# STM32G473 register map
File version: 2.2
CPU: CM4 r0p1, little endian, MPU, FPU, 4 interrupt priority bits
Registers are 32-bit, read-write, reset 0x0 unless marked. A register's access mark holds for its fields unless they carry their own. Offsets are from the block's base; [hi:lo] are bit positions; {n}, {i} and the like mark numbered series; 'fields as' and 'values as' point back to an identical list; <NAME> marks a mode.

## RCC — Reset and clock control
Base 0x40021000
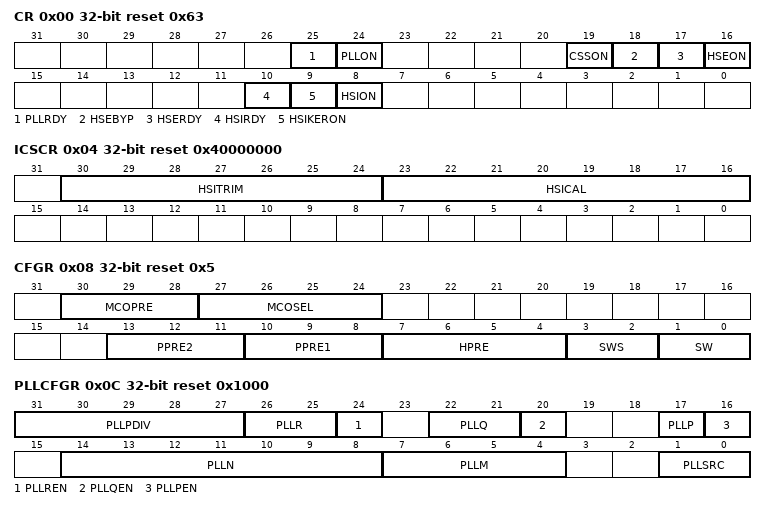
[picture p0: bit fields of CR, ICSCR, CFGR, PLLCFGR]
0x00 CR access per field reset 0x63 — Clock control register
  [25] PLLRDY ro — Main PLL clock ready flag Set by hardware to indicate that the main PLL is locked.
    0=NotReady (Clock not ready); 1=Ready (Clock ready)
  [24] PLLON rw — Main PLL enable Set and cleared by software to enable the main PLL. Cleared by hardware when entering Stop, Standby or Shutdown mode. This bit cannot be reset if the PLL clock is used as the system clock.
    0=Off (Clock Off); 1=On (Clock On)
  [19] CSSON rw — Clock security system enable Set by software to enable the clock security system. When CSSON is set, the clock detector is enabled by hardware when the HSE oscillator is ready, and disabled by hardware if a HSE clock failure is detected. This bit is set only and is cleared by reset.
    0=Off (Clock security system disabled (clock detector OFF)); 1=On (Clock security system enable (clock detector ON if the HSE is ready, OFF if not))
  [18] HSEBYP rw — HSE crystal oscillator bypass Set and cleared by software to bypass the oscillator with an external clock. The external clock must be enabled with the HSEON bit set, to be used by the device. The HSEBYP bit can be written only if the HSE oscillator is disabled.
    0=NotBypassed (HSE crystal oscillator not bypassed); 1=Bypassed (HSE crystal oscillator bypassed with external clock)
  [17] HSERDY ro — HSE clock ready flag Set by hardware to indicate that the HSE oscillator is stable. Note: Once the HSEON bit is cleared, HSERDY goes low after 6 HSE clock cycles.
    0=NotReady (Clock not ready); 1=Ready (Clock ready)
  [16] HSEON rw — HSE clock enable Set and cleared by software. Cleared by hardware to stop the HSE oscillator when entering Stop, Standby or Shutdown mode. This bit cannot be reset if the HSE oscillator is used directly or indirectly as the system clock.
    0=Off (Clock Off); 1=On (Clock On)
  [10] HSIRDY ro — HSI16 clock ready flag Set by hardware to indicate that HSI16 oscillator is stable. This bit is set only when HSI16 is enabled by software by setting HSION. Note: Once the HSION bit is cleared, HSIRDY goes low after 6 HSI16 clock cycles.
    0=NotReady (Clock not ready); 1=Ready (Clock ready)
  [9] HSIKERON rw — HSI16 always enable for peripheral kernels. Set and cleared by software to force HSI16 ON even in Stop modes. The HSI16 can only feed USARTs and I<sup>2</sup>Cs peripherals configured with HSI16 as kernel clock. Keeping the HSI16 ON in Stop mode allows to avoid slowing down the communication speed because of the HSI16 startup time. This bit has no effect on HSION value.
  [8] HSION rw — HSI16 clock enable Set and cleared by software. Cleared by hardware to stop the HSI16 oscillator when entering Stop, Standby or Shutdown mode. Set by hardware to force the HSI16 oscillator ON when STOPWUCK=1 or HSIASFS = 1 when leaving Stop modes, or in case of failure of the HSE crystal oscillator. This bit is set by hardware if the HSI16 is used directly or indirectly as system clock.
    0=Off (Clock Off); 1=On (Clock On)
0x04 ICSCR access per field reset 0x40000000 — Internal clock sources calibration register
  [30:24] HSITRIM rw — HSI16 clock trimming These bits provide an additional user-programmable trimming value that is added to the HSICAL[7:0] bits. It can be programmed to adjust to variations in voltage and temperature that influence the frequency of the HSI16. The default value is 16, which, when added to the HSICAL value, should trim the HSI16 to 16 MHz 1 %.
  [23:16] HSICAL ro — HSI16 clock calibration These bits are initialized at startup with the factory-programmed HSI16 calibration trim value. When HSITRIM is written, HSICAL is updated with the sum of HSITRIM and the factory trim value.
0x08 CFGR access per field reset 0x5 — Clock configuration register
  [30:28] MCOPRE rw — Microcontroller clock output prescaler These bits are set and cleared by software. It is highly recommended to change this prescaler before MCO output is enabled. Others: not allowed
    0=Div1 (MCO divided by 1); 1=Div2 (MCO divided by 2); 2=Div4 (MCO divided by 4); 3=Div8 (MCO divided by 8); 4=Div16 (MCO divided by 16)
  [27:24] MCOSEL rw — Microcontroller clock output Set and cleared by software. Others: Reserved Note: This clock output may have some truncated cycles at startup or during MCO clock source switching.
    0=None (MCO output disabled, no clock on MCO); 1=SYSCLK (SYSCLK system clock selected); 2=MSI (MSI clock selected); 3=HSI (HSI clock selected); 4=HSE (HSE clock selected); 5=PLL (Main PLL clock selected); 6=LSI (LSI clock selected); 7=LSE (LSE clock selected); 8=HSI48 (Internal HSI48 clock selected)
  [13:11] PPRE2 rw — APB2 prescaler Set and cleared by software to control the division factor of the APB2 clock (PCLK2). 0xx: HCLK not divided
    4=Div2 (HCLK divided by 2); 5=Div4 (HCLK divided by 4); 6=Div8 (HCLK divided by 8); 7=Div16 (HCLK divided by 16); other=Div1 (HCLK not divided)
  [10:8] PPRE1 rw — APB1 prescaler Set and cleared by software to control the division factor of the APB1 clock (PCLK1). 0xx: HCLK not divided
    values as PPRE2
  [7:4] HPRE rw — AHB prescaler Set and cleared by software to control the division factor of the AHB clock. Note: Depending on the device voltage range, the software has to set correctly these bits to ensure that the system frequency does not exceed the maximum allowed frequency (for more details please refer to Section 6.1.5: Dynamic voltage scaling management). After a write operation to these bits and before decreasing the voltage range, this register must be read to be sure that the new value has been taken into account. 0xxx: SYSCLK not divided
    8=Div2 (SYSCLK divided by 2); 9=Div4 (SYSCLK divided by 4); 10=Div8 (SYSCLK divided by 8); 11=Div16 (SYSCLK divided by 16); 12=Div64 (SYSCLK divided by 64); 13=Div128 (SYSCLK divided by 128); 14=Div256 (SYSCLK divided by 256); 15=Div512 (SYSCLK divided by 512); other=Div1 (SYSCLK not divided)
  [3:2] SWS ro — System clock switch status Set and cleared by hardware to indicate which clock source is used as system clock.
    0=MSI (MSI oscillator used as system clock); 1=HSI (HSI oscillator used as system clock); 2=HSE (HSE used as system clock); 3=PLL (PLL used as system clock)
  [1:0] SW rw — System clock switch Set and cleared by software to select system clock source (SYSCLK). Configured by hardware to force HSI16 oscillator selection when exiting stop and standby modes or in case of failure of the HSE oscillator.
    0=MSI (MSI selected as system clock); 1=HSI (HSI selected as system clock); 2=HSE (HSE selected as system clock); 3=PLL (PLL selected as system clock)
0x0C PLLCFGR reset 0x1000 — PLL configuration register
  [31:27] PLLPDIV — Main PLLP division factor Set and cleared by software to control the PLL P frequency. PLL P output clock frequency = VCO frequency / PLLPDIV. ....
    0=PLLP (pll_p_ck is controlled by PLLP); {v}=Div{v} (pll_p_ck = vco_ck / {v}) (v=2..31)
  [26:25] PLLR — Main PLL division factor for PLL R clock (system clock) Set and cleared by software to control the frequency of the main PLL output clock PLLCLK. This output can be selected as system clock. These bits can be written only if PLL is disabled. PLL R output clock frequency = VCO frequency / PLLR with PLLR = 2, 4, 6, or 8 Note: The software has to set these bits correctly not to exceed 170 MHz on this domain.
    0=Div2 (pll_r_ck = vco_ck / 2); 1=Div4 (pll_r_ck = vco_ck / 4); 2=Div6 (pll_r_ck = vco_ck / 6); 3=Div8 (pll_r_ck = vco_ck / 8)
  [24] PLLREN — PLL R clock output enable Set and reset by software to enable the PLL R clock output of the PLL (used as system clock). This bit cannot be written when PLL R clock output of the PLL is used as System Clock. In order to save power, when the PLL R clock output of the PLL is not used, the value of PLLREN should be 0.
  [22:21] PLLQ — Main PLL division factor for PLL Q clock. Set and cleared by software to control the frequency of the main PLL output clock PLL Q clock. This output can be selected for USB, RNG, SAI (48 MHz clock). These bits can be written only if PLL is disabled. PLL Q output clock frequency = VCO frequency / PLLQ with PLLQ = 2, 4, 6, or 8 Note: The software has to set these bits correctly not to exceed 170 MHz on this domain.
    0=Div2 (pll_q_ck = vco_ck / 2); 1=Div4 (pll_q_ck = vco_ck / 4); 2=Div6 (pll_q_ck = vco_ck / 6); 3=Div8 (pll_q_ck = vco_ck / 8)
  [20] PLLQEN — Main PLL Q clock output enable Set and reset by software to enable the PLL Q clock output of the PLL. In order to save power, when the PLL Q clock output of the PLL is not used, the value of PLLQEN should be 0.
  [17] PLLP — Main PLL division factor for PLL P clock. Set and cleared by software to control the frequency of the main PLL output clock PLL P clock. These bits can be written only if PLL is disabled. When the PLLPDIV[4:0] is set to 00000PLL P output clock frequency = VCO frequency / PLLP with PLLP =7, or 17 Note: The software has to set these bits correctly not to exceed 170 MHz on this domain.
    0=Div7 (pll_p_ck = vco_ck / 7); 1=Div17 (pll_p_ck = vco_ck / 17)
  [16] PLLPEN — Main PLL PLL P clock output enable Set and reset by software to enable the PLL P clock output of the PLL. In order to save power, when the PLL P clock output of the PLL is not used, the value of PLLPEN should be 0.
  [14:8] PLLN — Main PLL multiplication factor for VCO Set and cleared by software to control the multiplication factor of the VCO. These bits can be written only when the PLL is disabled. VCO output frequency = VCO input frequency x PLLN with 8 =< PLLN =< 127 ... ... Note: The software has to set correctly these bits to assure that the VCO output frequency is within the range defined in the device datasheet.
    {v}=Div{v} (pll_n_ck = vco_ck / {v}) (v=8..127)
  [7:4] PLLM — Division factor for the main PLL input clock Set and cleared by software to divide the PLL input clock before the VCO. These bits can be written only when all PLLs are disabled. VCO input frequency = PLL input clock frequency / PLLM with 1 <= PLLM <= 16 ... Note: The software has to set these bits correctly to ensure that the VCO input frequency is within the range defined in the device datasheet.
    {v}=Div{v+1} (pll_p_ck = vco_ck / {v+1}) (v=0..15)
  [1:0] PLLSRC — Main PLL entry clock source Set and cleared by software to select PLL clock source. These bits can be written only when PLL is disabled. In order to save power, when no PLL is used, the value of PLLSRC should be 00.
    0=None (No clock sent to PLL); 2=HSI16 (HSI16 sent to PLL input); 3=HSE (HSE sent to PLL input)
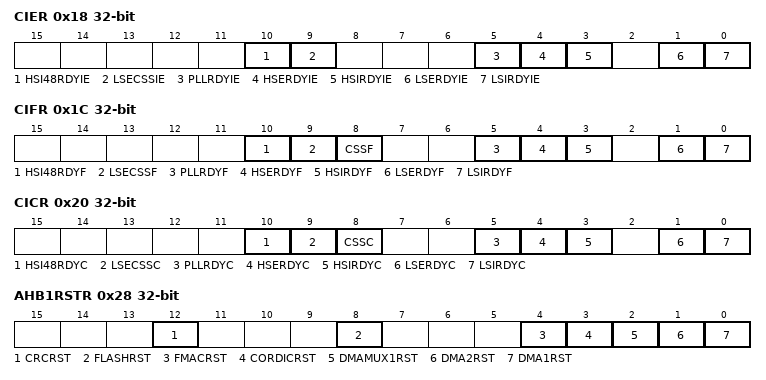
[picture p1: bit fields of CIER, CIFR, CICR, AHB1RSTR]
0x18 CIER — Clock interrupt enable register
  [10] HSI48RDYIE — HSI48 ready interrupt enable Set and cleared by software to enable/disable interrupt caused by the internal HSI48 oscillator.
  [9] LSECSSIE — LSE clock security system interrupt enable Set and cleared by software to enable/disable interrupt caused by the clock security system on LSE.
  [5] PLLRDYIE — PLL ready interrupt enable Set and cleared by software to enable/disable interrupt caused by PLL lock.
  [4] HSERDYIE — HSE ready interrupt enable Set and cleared by software to enable/disable interrupt caused by the HSE oscillator stabilization.
  [3] HSIRDYIE — HSI16 ready interrupt enable Set and cleared by software to enable/disable interrupt caused by the HSI16 oscillator stabilization.
  [1] LSERDYIE — LSE ready interrupt enable Set and cleared by software to enable/disable interrupt caused by the LSE oscillator stabilization.
  [0] LSIRDYIE — LSI ready interrupt enable Set and cleared by software to enable/disable interrupt caused by the LSI oscillator stabilization.
0x1C CIFR ro — Clock interrupt flag register
  [10] HSI48RDYF — HSI48 ready interrupt flag Set by hardware when the HSI48 clock becomes stable and HSI48RDYIE is set in a response to setting the HSI48ON (refer to Clock recovery RC register (RCC_CRRCR)). Cleared by software setting the HSI48RDYC bit.
  [9] LSECSSF — LSE Clock security system interrupt flag Set by hardware when a failure is detected in the LSE oscillator. Cleared by software setting the LSECSSC bit.
  [8] CSSF — Clock security system interrupt flag Set by hardware when a failure is detected in the HSE oscillator. Cleared by software setting the CSSC bit.
  [5] PLLRDYF — PLL ready interrupt flag Set by hardware when the PLL locks and PLLRDYDIE is set. Cleared by software setting the PLLRDYC bit.
  [4] HSERDYF — HSE ready interrupt flag Set by hardware when the HSE clock becomes stable and HSERDYDIE is set. Cleared by software setting the HSERDYC bit.
  [3] HSIRDYF — HSI16 ready interrupt flag Set by hardware when the HSI16 clock becomes stable and HSIRDYDIE is set in a response to setting the HSION (refer to Clock control register (RCC_CR)). When HSION is not set but the HSI16 oscillator is enabled by the peripheral through a clock request, this bit is not set and no interrupt is generated. Cleared by software setting the HSIRDYC bit.
  [1] LSERDYF — LSE ready interrupt flag Set by hardware when the LSE clock becomes stable and LSERDYDIE is set. Cleared by software setting the LSERDYC bit.
  [0] LSIRDYF — LSI ready interrupt flag Set by hardware when the LSI clock becomes stable and LSIRDYDIE is set. Cleared by software setting the LSIRDYC bit.
0x20 CICR wo — Clock interrupt clear register
  [10] HSI48RDYC — HSI48 oscillator ready interrupt clear This bit is set by software to clear the HSI48RDYF flag.
  [9] LSECSSC — LSE Clock security system interrupt clear This bit is set by software to clear the LSECSSF flag.
  [8] CSSC — Clock security system interrupt clear This bit is set by software to clear the CSSF flag.
  [5] PLLRDYC — PLL ready interrupt clear This bit is set by software to clear the PLLRDYF flag.
  [4] HSERDYC — HSE ready interrupt clear This bit is set by software to clear the HSERDYF flag.
  [3] HSIRDYC — HSI16 ready interrupt clear This bit is set software to clear the HSIRDYF flag.
  [1] LSERDYC — LSE ready interrupt clear This bit is set by software to clear the LSERDYF flag.
  [0] LSIRDYC — LSI ready interrupt clear This bit is set by software to clear the LSIRDYF flag.
0x28 AHB1RSTR — AHB1 peripheral reset register
  [all] fields
    1=Reset the selected module
  [12] CRCRST — CRC reset Set and cleared by software.
  [8] FLASHRST — Flash memory interface reset Set and cleared by software. This bit can be activated only when the Flash memory is in power down mode.
  [4] FMACRST — Set and cleared by software
  [3] CORDICRST — Set and cleared by software
  [2] DMAMUX1RST — Set and cleared by software.
  [1] DMA2RST — DMA2 reset Set and cleared by software.
  [0] DMA1RST — DMA1 reset Set and cleared by software.
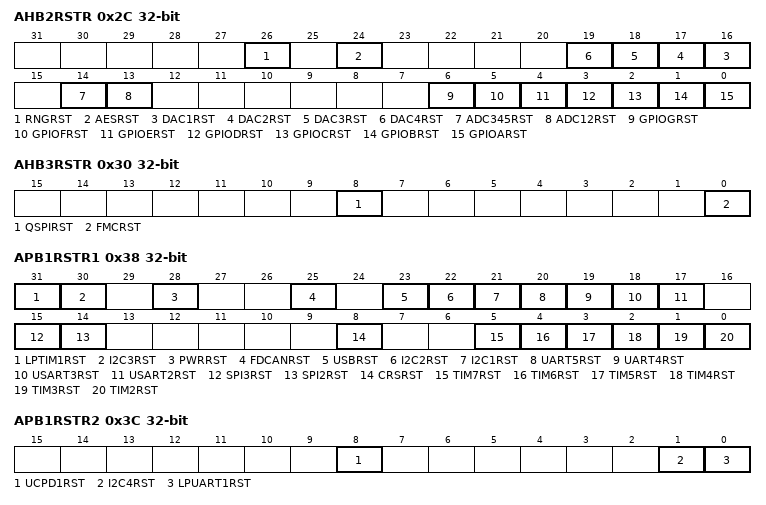
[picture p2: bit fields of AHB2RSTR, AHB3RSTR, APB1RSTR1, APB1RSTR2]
0x2C AHB2RSTR — AHB2 peripheral reset register
  [all] fields
    1=Reset the selected module
  [26] RNGRST — RNG reset Set and cleared by software.
  [24] AESRST — AESRST reset Set and cleared by software.
  [n+15] DAC{n}RST (n=1..4) — DAC{n} reset Set and cleared by software.
  [14] ADC345RST — ADC345 reset Set and cleared by software.
  [13] ADC12RST — ADC12 reset Set and cleared by software.
  [6] GPIOGRST — IO port G reset Set and cleared by software.
  [5] GPIOFRST — IO port F reset Set and cleared by software.
  [4] GPIOERST — IO port E reset Set and cleared by software.
  [3] GPIODRST — IO port D reset Set and cleared by software.
  [2] GPIOCRST — IO port C reset Set and cleared by software.
  [1] GPIOBRST — IO port B reset Set and cleared by software.
  [0] GPIOARST — IO port A reset Set and cleared by software.
0x30 AHB3RSTR — AHB3 peripheral reset register
  [8] QSPIRST — QUADSPI reset Set and cleared by software.
    1=Reset the selected module
  [0] FMCRST — Flexible static memory controller reset Set and cleared by software.
    1=Reset the selected module
0x38 APB1RSTR1 — APB1 peripheral reset register 1
  [all] fields
    1=Reset the selected module
  [31] LPTIM1RST — Low Power Timer 1 reset Set and cleared by software.
  [30] I2C3RST — I2C3 reset Set and cleared by software.
  [28] PWRRST — Power interface reset Set and cleared by software.
  [25] FDCANRST — FDCAN reset Set and reset by software.
  [23] USBRST — USB device reset Set and reset by software.
  [22] I2C2RST — I2C2 reset Set and cleared by software.
  [21] I2C1RST — I2C1 reset Set and cleared by software.
  [20] UART5RST — UART5 reset Set and cleared by software.
  [19] UART4RST — UART4 reset Set and cleared by software.
  [18] USART3RST — USART3 reset Set and cleared by software.
  [17] USART2RST — USART2 reset Set and cleared by software.
  [15] SPI3RST — SPI3 reset Set and cleared by software.
  [14] SPI2RST — SPI2 reset Set and cleared by software.
  [8] CRSRST — CRS reset Set and cleared by software.
  [5] TIM7RST — TIM7 timer reset Set and cleared by software.
  [4] TIM6RST — TIM6 timer reset Set and cleared by software.
  [3] TIM5RST — TIM5 timer reset Set and cleared by software.
  [2] TIM4RST — TIM3 timer reset Set and cleared by software.
  [1] TIM3RST — TIM3 timer reset Set and cleared by software.
  [0] TIM2RST — TIM2 timer reset Set and cleared by software.
0x3C APB1RSTR2 — APB1 peripheral reset register 2
  [all] fields
    1=Reset the selected module
  [8] UCPD1RST — UCPD1 reset Set and cleared by software.
  [1] I2C4RST — I2C4 reset Set and cleared by software
  [0] LPUART1RST — Low-power UART 1 reset Set and cleared by software.
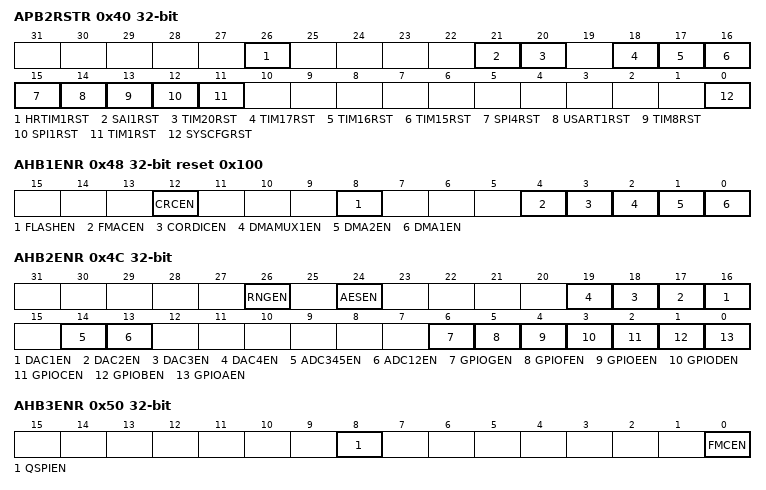
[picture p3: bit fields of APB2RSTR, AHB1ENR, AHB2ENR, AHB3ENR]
0x40 APB2RSTR — APB2 peripheral reset register
  [all] fields
    1=Reset the selected module
  [26] HRTIM1RST — HRTIM1 reset Set and cleared by software.
  [21] SAI1RST — Serial audio interface 1 (SAI1) reset Set and cleared by software.
  [20] TIM20RST — TIM20 reset Set and cleared by software.
  [18] TIM17RST — TIM17 timer reset Set and cleared by software.
  [17] TIM16RST — TIM16 timer reset Set and cleared by software.
  [16] TIM15RST — TIM15 timer reset Set and cleared by software.
  [15] SPI4RST — SPI4 reset Set and cleared by software.
  [14] USART1RST — USART1 reset Set and cleared by software.
  [13] TIM8RST — TIM8 timer reset Set and cleared by software.
  [12] SPI1RST — SPI1 reset Set and cleared by software.
  [11] TIM1RST — TIM1 timer reset Set and cleared by software.
  [0] SYSCFGRST — SYSCFG + COMP + OPAMP + VREFBUF reset
0x48 AHB1ENR reset 0x100 — AHB1 peripheral clock enable register
  [all] fields
    0=Disabled (The selected clock is disabled); 1=Enabled (The selected clock is enabled)
  [12] CRCEN — CRC clock enable Set and cleared by software.
  [8] FLASHEN — Flash memory interface clock enable Set and cleared by software. This bit can be disabled only when the Flash is in power down mode.
  [4] FMACEN — FMAC enable Set and reset by software.
  [3] CORDICEN — CORDIC clock enable Set and reset by software.
  [2] DMAMUX1EN — DMAMUX1 clock enable Set and reset by software.
  [1] DMA2EN — DMA2 clock enable Set and cleared by software.
  [0] DMA1EN — DMA1 clock enable Set and cleared by software.
0x4C AHB2ENR — AHB2 peripheral clock enable register
  [all] fields
    values as the fields of AHB1ENR
  [26] RNGEN — RNG enable Set and cleared by software.
  [24] AESEN — AES clock enable Set and cleared by software.
  [n+15] DAC{n}EN (n=1..4) — DAC{n} clock enable Set and cleared by software.
  [14] ADC345EN — ADC345 clock enable Set and cleared by software
  [13] ADC12EN — ADC12 clock enable Set and cleared by software.
  [6] GPIOGEN — IO port G clock enable Set and cleared by software.
  [5] GPIOFEN — IO port F clock enable Set and cleared by software.
  [4] GPIOEEN — IO port E clock enable Set and cleared by software.
  [3] GPIODEN — IO port D clock enable Set and cleared by software.
  [2] GPIOCEN — IO port C clock enable Set and cleared by software.
  [1] GPIOBEN — IO port B clock enable Set and cleared by software.
  [0] GPIOAEN — IO port A clock enable Set and cleared by software.
0x50 AHB3ENR — AHB3 peripheral clock enable register
  [8] QSPIEN — QUADSPI memory interface clock enable Set and cleared by software.
    values as the fields of AHB1ENR
  [0] FMCEN — Flexible static memory controller clock enable Set and cleared by software.
    values as the fields of AHB1ENR
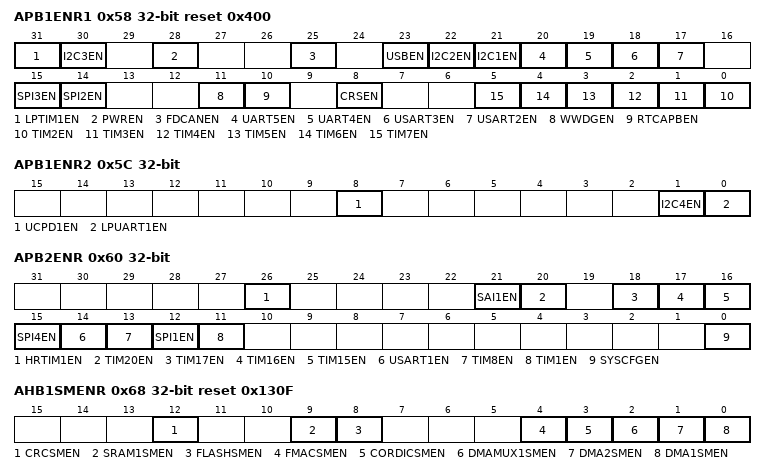
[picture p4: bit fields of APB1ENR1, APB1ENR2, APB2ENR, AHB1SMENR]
0x58 APB1ENR1 reset 0x400 — APB1 peripheral clock enable register 1
  [all] fields
    values as the fields of AHB1ENR
  [31] LPTIM1EN — Low power timer 1 clock enable Set and cleared by software.
  [30] I2C3EN — I2C3 clock enable Set and cleared by software.
  [28] PWREN — Power interface clock enable Set and cleared by software.
  [25] FDCANEN — FDCAN clock enable Set and cleared by software.
  [23] USBEN — USB device clock enable Set and cleared by software.
  [22] I2C2EN — I2C2 clock enable Set and cleared by software.
  [21] I2C1EN — I2C1 clock enable Set and cleared by software.
  [20] UART5EN — UART5 clock enable Set and cleared by software.
  [19] UART4EN — UART4 clock enable Set and cleared by software.
  [18] USART3EN — USART3 clock enable Set and cleared by software.
  [17] USART2EN — USART2 clock enable Set and cleared by software.
  [15] SPI3EN — SPI3 clock enable Set and cleared by software.
  [14] SPI2EN — SPI2 clock enable Set and cleared by software.
  [11] WWDGEN — Window watchdog clock enable Set by software to enable the window watchdog clock. Reset by hardware system reset. This bit can also be set by hardware if the WWDG_SW option bit is reset.
  [10] RTCAPBEN — RTC APB clock enable Set and cleared by software
  [8] CRSEN — CRS Recovery System clock enable Set and cleared by software.
  [n-2] TIM{n}EN (n=2..7) — TIM{n} timer clock enable Set and cleared by software.
0x5C APB1ENR2 — APB1 peripheral clock enable register 2
  [all] fields
    values as the fields of AHB1ENR
  [8] UCPD1EN — UCPD1 clock enable Set and cleared by software.
  [1] I2C4EN — I2C4 clock enable Set and cleared by software
  [0] LPUART1EN — Low power UART 1 clock enable Set and cleared by software.
0x60 APB2ENR — APB2 peripheral clock enable register
  [all] fields
    values as the fields of AHB1ENR
  [26] HRTIM1EN — HRTIM1 clock enable Set and cleared by software.
  [21] SAI1EN — SAI1 clock enable Set and cleared by software.
  [20] TIM20EN — TIM20 timer clock enable Set and cleared by software.
  [18] TIM17EN — TIM17 timer clock enable Set and cleared by software.
  [17] TIM16EN — TIM16 timer clock enable Set and cleared by software.
  [16] TIM15EN — TIM15 timer clock enable Set and cleared by software.
  [15] SPI4EN — SPI4 clock enable Set and cleared by software.
  [14] USART1EN — USART1clock enable Set and cleared by software.
  [13] TIM8EN — TIM8 timer clock enable Set and cleared by software.
  [12] SPI1EN — SPI1 clock enable Set and cleared by software.
  [11] TIM1EN — TIM1 timer clock enable Set and cleared by software.
  [0] SYSCFGEN — SYSCFG + COMP + VREFBUF + OPAMP clock enable Set and cleared by software.
0x68 AHB1SMENR reset 0x130F — AHB1 peripheral clocks enable in Sleep and Stop modes register
  [12] CRCSMEN — CRC clocks enable during Sleep and Stop modes Set and cleared by software.
  [9] SRAM1SMEN — SRAM1 interface clocks enable during Sleep and Stop modes Set and cleared by software.
  [8] FLASHSMEN — Flash memory interface clocks enable during Sleep and Stop modes Set and cleared by software.
  [4] FMACSMEN — FMACSM clock enable. Set and cleared by software.
  [3] CORDICSMEN — CORDICSM clock enable. Set and cleared by software.
  [2] DMAMUX1SMEN — DMAMUX1 clock enable during Sleep and Stop modes. Set and cleared by software.
  [1] DMA2SMEN — DMA2 clocks enable during Sleep and Stop modes Set and cleared by software during Sleep mode.
  [0] DMA1SMEN — DMA1 clocks enable during Sleep and Stop modes Set and cleared by software.
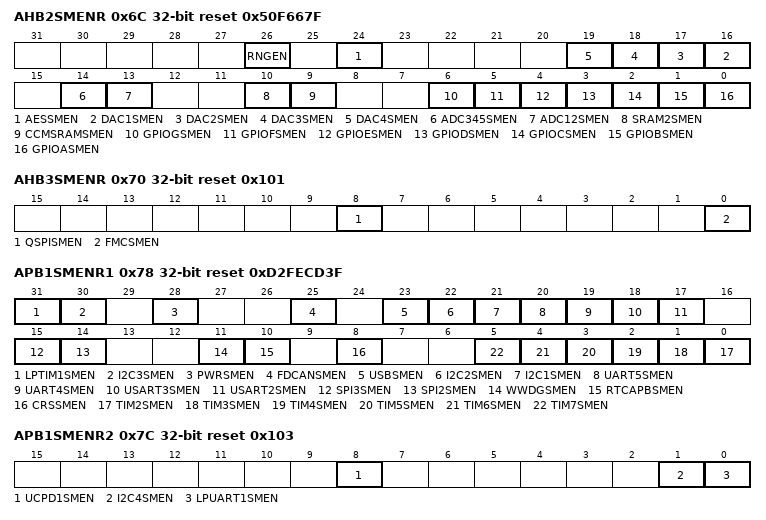
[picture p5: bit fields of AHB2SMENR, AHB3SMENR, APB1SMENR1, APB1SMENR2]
0x6C AHB2SMENR reset 0x50F667F — AHB2 peripheral clocks enable in Sleep and Stop modes register
  [26] RNGEN — RNG enable Set and cleared by software.
  [24] AESSMEN — AESM clocks enable Set and cleared by software.
  [n+15] DAC{n}SMEN (n=1..4) — DAC{n} clock enable Set and cleared by software.
  [14] ADC345SMEN — ADC345 clock enable Set and cleared by software.
  [13] ADC12SMEN — ADC12 clocks enable during Sleep and Stop modes Set and cleared by software.
  [10] SRAM2SMEN — SRAM2 interface clocks enable during Sleep and Stop modes Set and cleared by software.
  [9] CCMSRAMSMEN — CCM SRAM interface clocks enable during Sleep and Stop modes Set and cleared by software.
  [6] GPIOGSMEN — IO port G clocks enable during Sleep and Stop modes Set and cleared by software.
  [5] GPIOFSMEN — IO port F clocks enable during Sleep and Stop modes Set and cleared by software.
  [4] GPIOESMEN — IO port E clocks enable during Sleep and Stop modes Set and cleared by software.
  [3] GPIODSMEN — IO port D clocks enable during Sleep and Stop modes Set and cleared by software.
  [2] GPIOCSMEN — IO port C clocks enable during Sleep and Stop modes Set and cleared by software.
  [1] GPIOBSMEN — IO port B clocks enable during Sleep and Stop modes Set and cleared by software.
  [0] GPIOASMEN — IO port A clocks enable during Sleep and Stop modes Set and cleared by software.
0x70 AHB3SMENR reset 0x101 — AHB3 peripheral clocks enable in Sleep and Stop modes register
  [8] QSPISMEN — QUADSPI memory interface clock enable during Sleep and Stop modes Set and cleared by software.
  [0] FMCSMEN — Flexible static memory controller clocks enable during Sleep and Stop modes Set and cleared by software.
0x78 APB1SMENR1 reset 0xD2FECD3F — APB1 peripheral clocks enable in Sleep and Stop modes register 1
  [31] LPTIM1SMEN — Low power timer 1 clocks enable during Sleep and Stop modes Set and cleared by software.
  [30] I2C3SMEN — I2C3 clocks enable during Sleep and Stop modes Set and cleared by software.
  [28] PWRSMEN — Power interface clocks enable during Sleep and Stop modes Set and cleared by software.
  [25] FDCANSMEN — FDCAN clocks enable during Sleep and Stop modes Set and cleared by software.
  [23] USBSMEN — USB device clocks enable during Sleep and Stop modes Set and cleared by software.
  [22] I2C2SMEN — I2C2 clocks enable during Sleep and Stop modes Set and cleared by software.
  [21] I2C1SMEN — I2C1 clocks enable during Sleep and Stop modes Set and cleared by software.
  [20] UART5SMEN — UART5 clocks enable during Sleep and Stop modes Set and cleared by software.
  [19] UART4SMEN — UART4 clocks enable during Sleep and Stop modes Set and cleared by software.
  [18] USART3SMEN — USART3 clocks enable during Sleep and Stop modes Set and cleared by software.
  [17] USART2SMEN — USART2 clocks enable during Sleep and Stop modes Set and cleared by software.
  [15] SPI3SMEN — SPI3 clocks enable during Sleep and Stop modes Set and cleared by software.
  [14] SPI2SMEN — SPI2 clocks enable during Sleep and Stop modes Set and cleared by software.
  [11] WWDGSMEN — Window watchdog clocks enable during Sleep and Stop modes Set and cleared by software. This bit is forced to 1 by hardware when the hardware WWDG option is activated.
  [10] RTCAPBSMEN — RTC APB clock enable during Sleep and Stop modes Set and cleared by software
  [8] CRSSMEN — CRS timer clocks enable during Sleep and Stop modes Set and cleared by software.
  [n-2] TIM{n}SMEN (n=2..7) — TIM{n} timer clocks enable during Sleep and Stop modes Set and cleared by software.
0x7C APB1SMENR2 reset 0x103 — APB1 peripheral clocks enable in Sleep and Stop modes register 2
  [8] UCPD1SMEN — UCPD1 clocks enable during Sleep and Stop modes Set and cleared by software.
  [1] I2C4SMEN — I2C4 clocks enable during Sleep and Stop modes Set and cleared by software
  [0] LPUART1SMEN — Low power UART 1 clocks enable during Sleep and Stop modes Set and cleared by software.
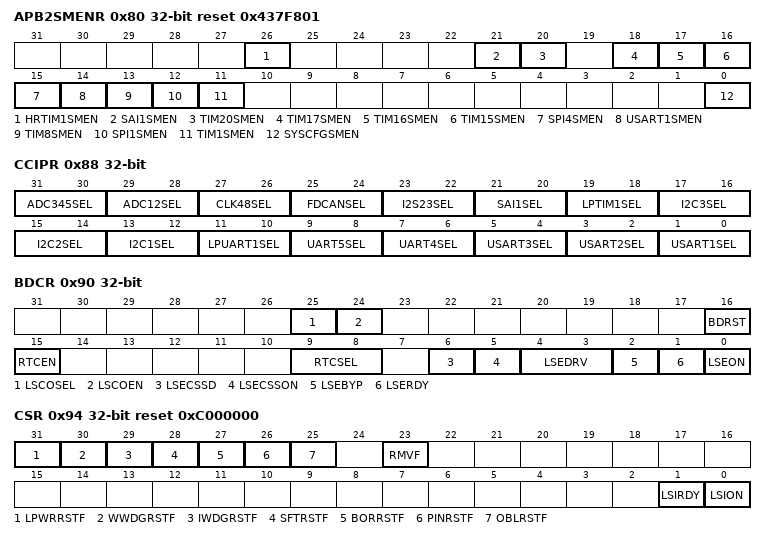
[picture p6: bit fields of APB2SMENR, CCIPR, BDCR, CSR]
0x80 APB2SMENR reset 0x437F801 — APB2 peripheral clocks enable in Sleep and Stop modes register
  [26] HRTIM1SMEN — HRTIM1 timer clocks enable during Sleep and Stop modes Set and cleared by software.
  [21] SAI1SMEN — SAI1 clocks enable during Sleep and Stop modes Set and cleared by software.
  [20] TIM20SMEN — TIM20 timer clocks enable during Sleep and Stop modes Set and cleared by software.
  [18] TIM17SMEN — TIM17 timer clocks enable during Sleep and Stop modes Set and cleared by software.
  [17] TIM16SMEN — TIM16 timer clocks enable during Sleep and Stop modes Set and cleared by software.
  [16] TIM15SMEN — TIM15 timer clocks enable during Sleep and Stop modes Set and cleared by software.
  [15] SPI4SMEN — SPI4 timer clocks enable during Sleep and Stop modes Set and cleared by software.
  [14] USART1SMEN — USART1clocks enable during Sleep and Stop modes Set and cleared by software.
  [13] TIM8SMEN — TIM8 timer clocks enable during Sleep and Stop modes Set and cleared by software.
  [12] SPI1SMEN — SPI1 clocks enable during Sleep and Stop modes Set and cleared by software.
  [11] TIM1SMEN — TIM1 timer clocks enable during Sleep and Stop modes Set and cleared by software.
  [0] SYSCFGSMEN — SYSCFG + COMP + VREFBUF + OPAMP clocks enable during Sleep and Stop modes Set and cleared by software.
0x88 CCIPR — Peripherals independent clock configuration register
  [31:30] ADC345SEL — ADC3/4/5 clock source selection These bits are set and cleared by software to select the clock source used by the ADC345 interface.
    0=None (No clock selected for ADC); 1=PLLP (PLL 'P' clock selected for ADC); 2=System clock selected for ADC
  [29:28] ADC12SEL — ADC1/2 clock source selection These bits are set and cleared by software to select the clock source used by the ADC interface.
    values as ADC345SEL
  [27:26] CLK48SEL — 48 MHz clock source selection These bits are set and cleared by software to select the 48 MHz clock source used by USB device FS and RNG.
    0=HSI48 (HSI48 clock selected as 48MHz clock); 2=PLLQ (PLL 'Q' (PLL48M1CLK) clock selected as 48MHz clock)
  [25:24] FDCANSEL
    0=HSE (HSE clock selected as FDCAN clock); 1=PLLQ (PLL 'Q' clock selected as FDCAN clock); 2=PCLK (PCLK clock selected as FDCAN clock)
  [23:22] I2S23SEL — clock source selection These bits are set and cleared by software to select the I2S23 clock source.
    0=System clock selected as I2S23 clock; 1=PLLQ (PLL 'Q' clock selected as I2S23 clock); 2=I2S_CKIN (Clock provided on I2S_CKIN pin is selected as I2S23 clock); 3=HSI16 (HSI16 clock selected as I2S23 clock)
  [21:20] SAI1SEL — clock source selection These bits are set and cleared by software to select the SAI clock source.
    0=System clock selected as SAI clock; 1=PLLQ (PLL 'Q' clock selected as SAI clock); 2=I2S_CKIN (Clock provided on I2S_CKIN pin is selected as SAI clock); 3=HSI16 (HSI16 clock selected as SAI clock)
  [19:18] LPTIM1SEL — Low power timer 1 clock source selection These bits are set and cleared by software to select the LPTIM1 clock source.
    0=PCLK (PCLK clock selected as LPTIM1 clock); 1=LSI (LSI clock selected as LPTIM1 clock); 2=HSI16 (HSI16 clock selected as LPTIM1 clock); 3=LSE (LSE clock selected as LPTIM1 clock)
  [17:16] I2C3SEL — I2C3 clock source selection These bits are set and cleared by software to select the I2C3 clock source.
    0=PCLK (PCLK clock selected as I2C clock); 1=System clock (SYSCLK) selected as I2C clock; 2=HSI16 (HSI16 clock selected as I2C clock)
  [15:14] I2C2SEL — I2C2 clock source selection These bits are set and cleared by software to select the I2C2 clock source.
    values as I2C3SEL
  [13:12] I2C1SEL — I2C1 clock source selection These bits are set and cleared by software to select the I2C1 clock source.
    values as I2C3SEL
  [11:10] LPUART1SEL — LPUART1 clock source selection These bits are set and cleared by software to select the LPUART1 clock source.
    0=PCLK (PCLK clock selected as UART clock); 1=System clock (SYSCLK) selected as UART clock; 2=HSI16 (HSI16 clock selected as UART clock); 3=LSE (LSE clock selected as UART clock)
  [9:8] UART5SEL — UART5 clock source selection These bits are set and cleared by software to select the UART5 clock source.
    values as LPUART1SEL
  [7:6] UART4SEL — UART4 clock source selection This bit is set and cleared by software to select the UART4 clock source.
    values as LPUART1SEL
  [5:4] USART3SEL — USART3 clock source selection This bit is set and cleared by software to select the USART3 clock source.
  [3:2] USART2SEL — USART2 clock source selection This bit is set and cleared by software to select the USART2 clock source.
  [1:0] USART1SEL — USART1 clock source selection This bit is set and cleared by software to select the USART1 clock source.
0x90 BDCR access per field — RTC domain control register
  [25] LSCOSEL rw — Low speed clock output selection Set and cleared by software.
    0=LSI (LSI clock selected); 1=LSE (LSE clock selected)
  [24] LSCOEN rw — Low speed clock output enable Set and cleared by software.
    0=Disabled (LSCO disabled); 1=Enabled (LSCO enabled)
  [16] BDRST rw — RTC domain software reset Set and cleared by software.
    0=Disabled (Reset not activated); 1=Enabled (Reset the entire RTC domain)
  [15] RTCEN rw — RTC clock enable Set and cleared by software.
    0=Disabled (RTC clock disabled); 1=Enabled (RTC clock enabled)
  [9:8] RTCSEL rw — RTC clock source selection Set by software to select the clock source for the RTC. Once the RTC clock source has been selected, it cannot be changed anymore unless the RTC domain is reset, or unless a failure is detected on LSE (LSECSSD is set). The BDRST bit can be used to reset them.
    0=NoClock; 1=LSE (LSE oscillator clock used as RTC clock); 2=LSI (LSI oscillator clock used as RTC clock); 3=HSE (HSE oscillator clock divided by a prescaler used as RTC clock)
  [6] LSECSSD ro — CSS on LSE failure Detection Set by hardware to indicate when a failure has been detected by the Clock Security System on the external 32 kHz oscillator (LSE).
    0=No failure detected on LSE (32 kHz oscillator); 1=Failure detected on LSE (32 kHz oscillator)
  [5] LSECSSON rw — CSS on LSE enable Set by software to enable the Clock Security System on LSE (32 kHz oscillator). LSECSSON must be enabled after the LSE oscillator is enabled (LSEON bit enabled) and ready (LSERDY flag set by hardware), and after the RTCSEL bit is selected. Once enabled this bit cannot be disabled, except after a LSE failure detection (LSECSSD =1). In that case the software MUST disable the LSECSSON bit.
    0=Off (CSS on LSE (32 kHz external oscillator) OFF); 1=On (CSS on LSE (32 kHz external oscillator) ON)
  [4:3] LSEDRV rw — LSE oscillator drive capability Set by software to modulate the LSE oscillators drive capability. The oscillator is in Xtal mode when it is not in bypass mode.
    0=Lower ('Xtal mode' lower driving capability); 1=MediumLow ('Xtal mode' medium low driving capability); 2=MediumHigh ('Xtal mode' medium high driving capability); 3=Higher ('Xtal mode' higher driving capability)
  [2] LSEBYP rw — LSE oscillator bypass Set and cleared by software to bypass oscillator in debug mode. This bit can be written only when the external 32 kHz oscillator is disabled (LSEON=0 and LSERDY=0).
    0=NotBypassed (LSE crystal oscillator not bypassed); 1=Bypassed (LSE crystal oscillator bypassed with external clock)
  [1] LSERDY ro — LSE oscillator ready Set and cleared by hardware to indicate when the external 32 kHz oscillator is stable. After the LSEON bit is cleared, LSERDY goes low after 6 external low-speed oscillator clock cycles.
    0=NotReady (LSE clock not ready); 1=Ready (LSE clock ready)
  [0] LSEON rw — LSE oscillator enable Set and cleared by software.
    0=Off (LSE only enabled when requested by a peripheral or system function); 1=On (LSE enabled always generated by RCC)
0x94 CSR access per field reset 0xC000000 — Control/status register
  [31] LPWRRSTF ro — Low-power reset flag Set by hardware when a reset occurs due to illegal Stop, Standby or Shutdown mode entry. Cleared by writing to the RMVF bit.
    0=No reset has occured; 1=Reset (A reset has occured)
  [30] WWDGRSTF ro — Window watchdog reset flag Set by hardware when a window watchdog reset occurs. Cleared by writing to the RMVF bit.
    0=No reset has occured; 1=Reset (A reset has occured)
  [29] IWDGRSTF ro — Independent window watchdog reset flag Set by hardware when an independent watchdog reset domain occurs. Cleared by writing to the RMVF bit.
    0=No reset has occured; 1=Reset (A reset has occured)
  [28] SFTRSTF ro — Software reset flag Set by hardware when a software reset occurs. Cleared by writing to the RMVF bit.
    0=No reset has occured; 1=Reset (A reset has occured)
  [27] BORRSTF ro — BOR flag Set by hardware when a BOR occurs. Cleared by writing to the RMVF bit.
    0=No reset has occured; 1=Reset (A reset has occured)
  [26] PINRSTF ro — Pin reset flag Set by hardware when a reset from the NRST pin occurs. Cleared by writing to the RMVF bit.
    0=No reset has occured; 1=Reset (A reset has occured)
  [25] OBLRSTF ro — Option byte loader reset flag Set by hardware when a reset from the Option Byte loading occurs. Cleared by writing to the RMVF bit.
    0=No reset has occured; 1=Reset (A reset has occured)
  [23] RMVF rw — Remove reset flag Set by software to clear the reset flags.
    on write: 1=Clears the reset flag
  [1] LSIRDY ro — LSI oscillator ready Set and cleared by hardware to indicate when the LSI oscillator is stable. After the LSION bit is cleared, LSIRDY goes low after 3 LSI oscillator clock cycles. This bit can be set even if LSION = 0 if the LSI is requested by the Clock Security System on LSE, by the Independent Watchdog or by the RTC.
    0=NotReady (LSI oscillator not ready); 1=Ready (LSI oscillator ready)
  [0] LSION rw — LSI oscillator enable Set and cleared by software.
    0=Off (LSI oscillator Off); 1=On (LSI oscillator On)
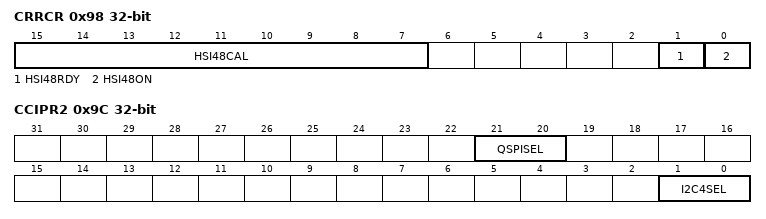
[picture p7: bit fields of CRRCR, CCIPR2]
0x98 CRRCR access per field — Clock recovery RC register
  [15:7] HSI48CAL ro — HSI48 clock calibration These bits are initialized at startup with the factory-programmed HSI48 calibration trim value. They are ready only.
  [1] HSI48RDY ro — HSI48 clock ready flag Set by hardware to indicate that HSI48 oscillator is stable. This bit is set only when HSI48 is enabled by software by setting HSI48ON.
  [0] HSI48ON rw — HSI48 clock enable Set and cleared by software. Cleared by hardware to stop the HSI48 when entering in Stop, Standby or Shutdown modes.
0x9C CCIPR2 — Peripherals independent clock configuration register
  [21:20] QSPISEL — QUADSPI clock source selection Set and reset by software.
    0=System clock selected as QUADSPI kernel clock; 1=HSI16 (HSI16 clock selected as QUADSPI kernel clock); 2=PLLQ (PLL 'Q' clock selected as QUADSPI kernel clock)
  [1:0] I2C4SEL — I2C4 clock source selection These bits are set and cleared by software to select the I2C4 clock source.
    values as CCIPR.I2C3SEL
